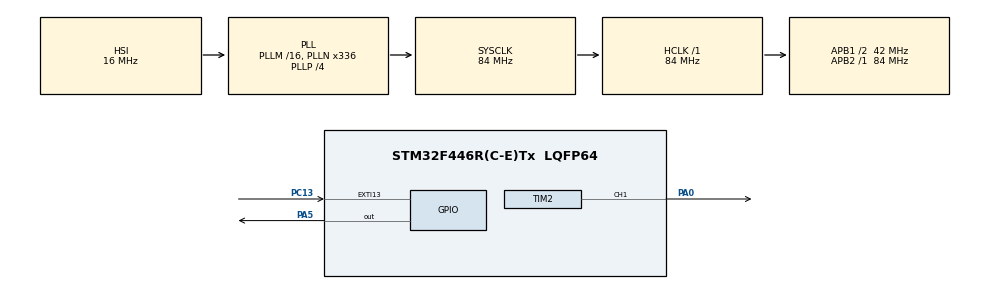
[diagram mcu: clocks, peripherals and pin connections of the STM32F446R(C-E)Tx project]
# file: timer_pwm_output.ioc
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Mcu.Family=STM32F4
Mcu.Name=STM32F446R(C-E)Tx
Mcu.Package=LQFP64
NUCLEO-F446RE.BUTTON=1
NUCLEO-F446RE.LD1=true
NVIC.EXTI15_10_IRQn=true\:0\:0\:false\:false\:true\:false\:true\:true
NVIC.PriorityGroup=NVIC_PRIORITYGROUP_0
NVIC.TIM2_IRQn=true\:0\:0\:false\:false\:true\:true\:true\:true
PA0-WKUP.Signal=S_TIM2_CH1_ETR
PA13.GPIO_Label=TMS
PA13.Signal=SYS_JTMS-SWDIO
PA14.GPIO_Label=TCK
PA14.Signal=SYS_JTCK-SWCLK
PA2.GPIO_Label=USART_TX
PA2.Signal=USART2_TX
PA3.GPIO_Label=USART_RX
PA3.Signal=USART2_RX
PA5.Signal=GPIO_Output
PB3.GPIO_Label=SWO
PB3.Signal=SYS_JTDO-SWO
PC13.Signal=GPXTI13
PC14-OSC32_IN.Signal=RCC_OSC32_IN
PC15-OSC32_OUT.Signal=RCC_OSC32_OUT
PH0-OSC_IN.Signal=RCC_OSC_IN
PH1-OSC_OUT.Signal=RCC_OSC_OUT
ProjectManager.HeapSize=0x200
ProjectManager.StackSize=0x400
ProjectManager.TargetToolchain=STM32CubeIDE
RCC.AHBFreq_Value=84000000
RCC.APB1CLKDivider=RCC_HCLK_DIV2
RCC.APB1Freq_Value=42000000
RCC.APB1TimFreq_Value=84000000
RCC.APB2Freq_Value=84000000
RCC.APB2TimFreq_Value=84000000
RCC.CortexFreq_Value=84000000
RCC.FLatency-AdvancedSettings=FLASH_LATENCY_2
RCC.HCLKFreq_Value=84000000
RCC.HSE_VALUE=8000000
RCC.HSI_VALUE=16000000
RCC.LSE_VALUE=32768
RCC.PLLN=336
RCC.PLLP=RCC_PLLP_DIV4
RCC.SYSCLKFreq_VALUE=84000000
RCC.SYSCLKSource=RCC_SYSCLKSOURCE_PLLCLK
RCC.USBFreq_Value=168000000
RCC.VCOOutputFreq_Value=336000000
SH.S_TIM2_CH1_ETR.0=TIM2_CH1,PWM Generation1 CH1
TIM2.Channel-PWM\ Generation1\ CH1=TIM_CHANNEL_1
TIM2.Period=999
TIM2.Prescaler=15
VP_NUCLEO-F446RE_VS_BSP_COMMON.Mode=COMMON
board=NUCLEO-F446RE

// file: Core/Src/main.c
/* USER CODE BEGIN Header */
/**
  ******************************************************************************
  * @file           : main.c
  * @brief          : Variation de l'intensité d'une LED (Effet Breathing) par PWM
  * @project        : timer_pwm_output
  * @author         : Oponou KOKOLA
  *
  * @details        :
  *   1. Configuration d'un Timer matériel (TIM2) en mode PWM Output (Canal 1, PA0 = LDE).
  *   2. Utilisation de la période (ARR = 999) pour définir la résolution du rapport cyclique.
  *   3. Variation progressive et automatique de la luminosité dans la boucle while(1).
  *   4. Cadence de l'effet donnée par HAL_Delay (bloquant : le CPU attend).
  ******************************************************************************
  */
/* USER CODE END Header */

#include "main.h"

/* USER CODE BEGIN Includes */
#include <stdbool.h>
#include <stdint.h>
/* USER CODE END Includes */

TIM_HandleTypeDef htim2;

/* USER CODE BEGIN PV */
#define PWM_MAX   999U   /* = ARR : rapport cyclique maximal */

uint32_t luminosite = 0;
bool montee = true;
/* USER CODE END PV */

void SystemClock_Config(void);
static void MX_GPIO_Init(void);
static void MX_TIM2_Init(void);

int main(void)
{
  HAL_Init();
  SystemClock_Config();

  MX_GPIO_Init();
  MX_TIM2_Init();

  /* USER CODE BEGIN 2 */

  /* Démarrage du signal PWM sur le Timer 2, Canal 1 */
  HAL_TIM_PWM_Start(&htim2, TIM_CHANNEL_1);
  /* USER CODE END 2 */

  /* Infinite loop */
  while (1)
  {
    /* USER CODE BEGIN 3 */
    if (montee)
    {
      if (luminosite < PWM_MAX)
      {
        luminosite++;
      }
      else
      {
        montee = false;
      }
    }
    else
    {

      if (luminosite > 0)
      {
        luminosite--;
      }
      else
      {
        montee = true;
      }
    }

    __HAL_TIM_SET_COMPARE(&htim2, TIM_CHANNEL_1, luminosite);

    HAL_Delay(2);
    /* USER CODE END 3 */
  }
}

void SystemClock_Config(void)
{
  RCC_OscInitTypeDef RCC_OscInitStruct = {0};
  RCC_ClkInitTypeDef RCC_ClkInitStruct = {0};

  __HAL_RCC_PWR_CLK_ENABLE();
  __HAL_PWR_VOLTAGESCALING_CONFIG(PWR_REGULATOR_VOLTAGE_SCALE3);

  RCC_OscInitStruct.OscillatorType = RCC_OSCILLATORTYPE_HSI;
  RCC_OscInitStruct.HSIState = RCC_HSI_ON;
  RCC_OscInitStruct.HSICalibrationValue = RCC_HSICALIBRATION_DEFAULT;
  RCC_OscInitStruct.PLL.PLLState = RCC_PLL_ON;
  RCC_OscInitStruct.PLL.PLLSource = RCC_PLLSOURCE_HSI;
  RCC_OscInitStruct.PLL.PLLM = 16;
  RCC_OscInitStruct.PLL.PLLN = 336;
  RCC_OscInitStruct.PLL.PLLP = RCC_PLLP_DIV4;
  RCC_OscInitStruct.PLL.PLLQ = 2;
  RCC_OscInitStruct.PLL.PLLR = 2;
  if (HAL_RCC_OscConfig(&RCC_OscInitStruct) != HAL_OK)
  {
    Error_Handler();
  }

  RCC_ClkInitStruct.ClockType = RCC_CLOCKTYPE_HCLK|RCC_CLOCKTYPE_SYSCLK
                              |RCC_CLOCKTYPE_PCLK1|RCC_CLOCKTYPE_PCLK2;
  RCC_ClkInitStruct.SYSCLKSource = RCC_SYSCLKSOURCE_PLLCLK;
  RCC_ClkInitStruct.AHBCLKDivider = RCC_SYSCLK_DIV1;
  RCC_ClkInitStruct.APB1CLKDivider = RCC_HCLK_DIV2;
  RCC_ClkInitStruct.APB2CLKDivider = RCC_HCLK_DIV1;

  if (HAL_RCC_ClockConfig(&RCC_ClkInitStruct, FLASH_LATENCY_2) != HAL_OK)
  {
    Error_Handler();
  }
}

static void MX_TIM2_Init(void)
{
  TIM_MasterConfigTypeDef sMasterConfig = {0};
  TIM_OC_InitTypeDef sConfigOC = {0};

  htim2.Instance = TIM2;
  htim2.Init.Prescaler = 15;
  htim2.Init.CounterMode = TIM_COUNTERMODE_UP;
  htim2.Init.Period = 999;
  htim2.Init.ClockDivision = TIM_CLOCKDIVISION_DIV1;
  htim2.Init.AutoReloadPreload = TIM_AUTORELOAD_PRELOAD_DISABLE;

  if (HAL_TIM_PWM_Init(&htim2) != HAL_OK)
  {
    Error_Handler();
  }

  sMasterConfig.MasterOutputTrigger = TIM_TRGO_RESET;
  sMasterConfig.MasterSlaveMode = TIM_MASTERSLAVEMODE_DISABLE;

  if (HAL_TIMEx_MasterConfigSynchronization(&htim2, &sMasterConfig) != HAL_OK)
  {
    Error_Handler();
  }

  sConfigOC.OCMode = TIM_OCMODE_PWM1;
  sConfigOC.Pulse = 0;
  sConfigOC.OCPolarity = TIM_OCPOLARITY_HIGH;
  sConfigOC.OCFastMode = TIM_OCFAST_DISABLE;

  if (HAL_TIM_PWM_ConfigChannel(&htim2, &sConfigOC, TIM_CHANNEL_1) != HAL_OK)
  {
    Error_Handler();
  }

  HAL_TIM_MspPostInit(&htim2);
}

static void MX_GPIO_Init(void)
{
  __HAL_RCC_GPIOC_CLK_ENABLE();
  __HAL_RCC_GPIOH_CLK_ENABLE();
  __HAL_RCC_GPIOA_CLK_ENABLE();
  __HAL_RCC_GPIOB_CLK_ENABLE();
}

void Error_Handler(void)
{
  __disable_irq();
  while (1)
  {
  }
}
